# STM32L562 register map
File version: 1.1
Registers are 32-bit, read-write, reset 0x0 unless marked. A register's access mark holds for its fields unless they carry their own. Offsets are from the block's base; lines under a group give offsets from that group; [hi:lo] are bit positions; {n}, {i} and the like mark numbered series; 'fields as' and 'values as' point back to an identical list; <NAME> marks a mode.

## Memory map
0x420C0400 HASH size 0x400

## Interrupts
96 HASH

## HASH
Base 0x420C0400
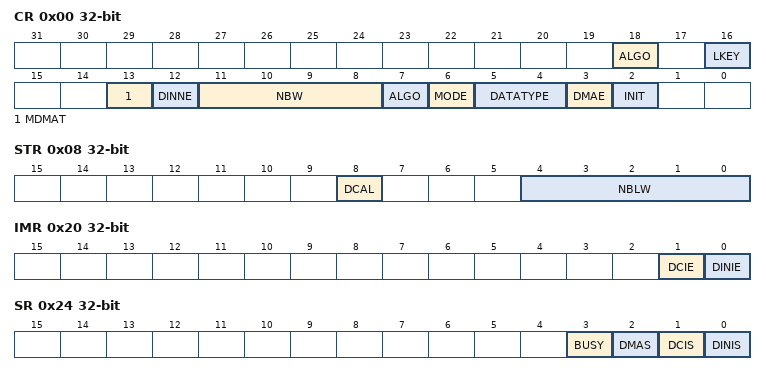
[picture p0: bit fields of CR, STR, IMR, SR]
0x00 CR
  [18] ALGO, [16] LKEY, [13] MDMAT, [12] DINNE, [11:8] NBW, [7] ALGO, [6] MODE, [5:4] DATATYPE, [3] DMAE, [2] INIT
0x04 DIN
  [31:0] DATAIN
0x08 STR
  [8] DCAL, [4:0] NBLW
{0xC+4i} HRA{i} (i=0..4)
  [31:0] H{i}
0x20 IMR
  [1] DCIE, [0] DINIE
0x24 SR
  [3] BUSY, [2] DMAS, [1] DCIS, [0] DINIS
{0xF8+4i} CSR{i} (i=0..53)
{0x310+4i} HR{i} (i=0..7)
  [31:0] H{i}
